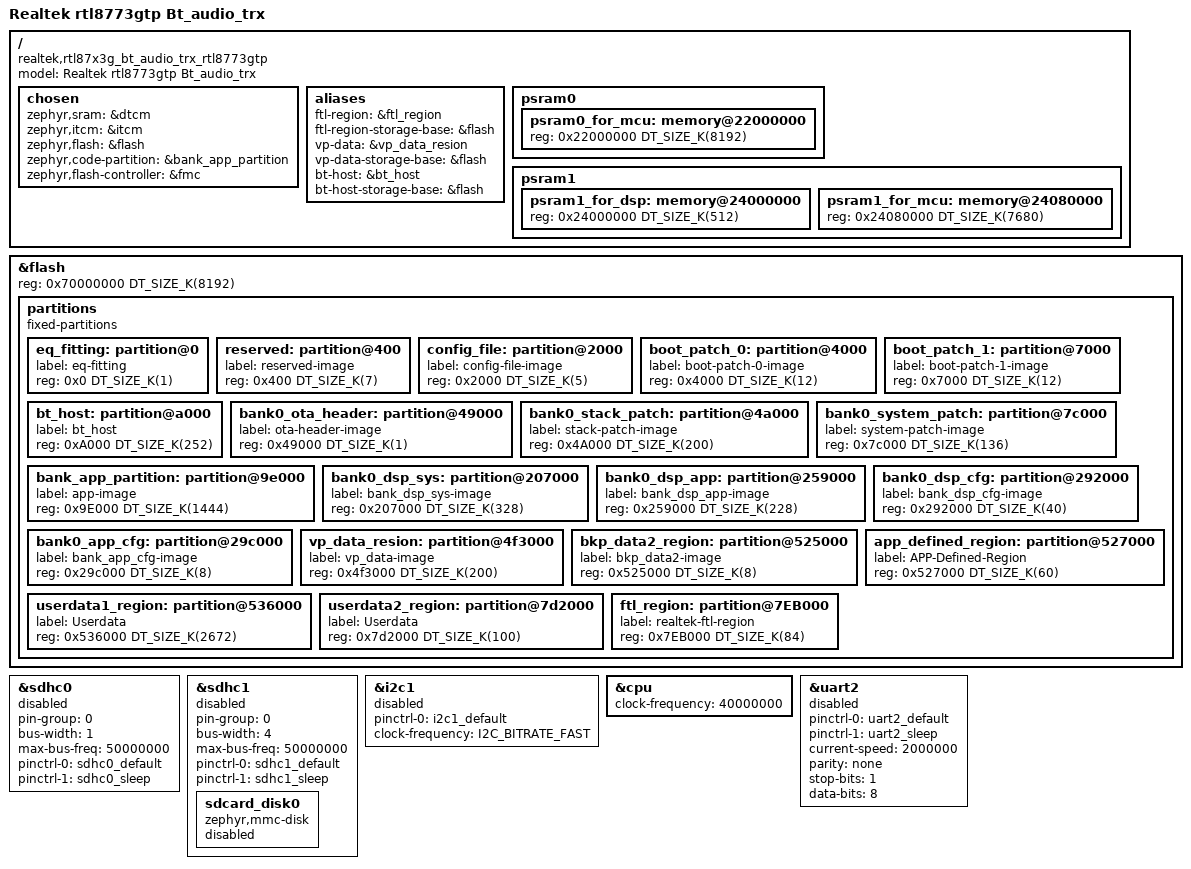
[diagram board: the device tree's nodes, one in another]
/*
 * Copyright (c) 2026, Realtek Semiconductor Corporation
 *
 * SPDX-License-Identifier: LicenseRef-Realtek-5-Clause
 */

/dts-v1/;
#include <realtek/rtl87x3g.dtsi>
#include "rtl87x3g_bt_audio_trx_rtl8783gbf-pinctrl.dtsi"
#include "board_pin_assignments/rtl8783gbf/board.h"
/ {
	model = "Realtek rtl8773gtp Bt_audio_trx";
	compatible = "realtek,rtl87x3g_bt_audio_trx_rtl8773gtp";
	chosen {
		zephyr,sram = &dtcm;
		zephyr,itcm = &itcm;
		zephyr,flash = &flash;
		zephyr,code-partition = &bank_app_partition;
//		zephyr,console = &uart2;
//		zephyr,shell-uart = &uart2;
		zephyr,flash-controller = &fmc;
	};
	/* These aliases are used by soc.c */
	aliases {
		ftl-region = &ftl_region;
		ftl-region-storage-base = &flash;
		vp-data = &vp_data_resion;
		vp-data-storage-base = &flash;
		bt-host = &bt_host;
		bt-host-storage-base = &flash;
	};
	
	psram0:psram0 {
		#address-cells = <1>;
		#size-cells = <1>;
		psram0_for_mcu: memory@22000000{
			device_type = "psram 0 region";
			reg = <0x22000000 DT_SIZE_K(8192)>;
		};
	};

	psram1:psram1 {
		#address-cells = <1>;
		#size-cells = <1>;

		psram1_for_dsp: memory@24000000{
			device_type = "psram 1 region for dsp";
			reg = <0x24000000 DT_SIZE_K(512)>;
		};
		
		psram1_for_mcu: memory@24080000{
			device_type = "psram 1 region";
			reg = <0x24080000 DT_SIZE_K(7680)>;
		};
	};
};

&flash
{
	reg = <0x70000000 DT_SIZE_K(8192)>;
	partitions {
	    compatible = "fixed-partitions";
		#address-cells = <1>;
		#size-cells = <1>;
		eq_fitting: partition@0 {
			label = "eq-fitting";
			reg = <0x0 DT_SIZE_K(1)>;
		};
		reserved: partition@400 {
			label = "reserved-image";
			reg = <0x400 DT_SIZE_K(7)>;
		};
		config_file: partition@2000 {
			label = "config-file-image";
			reg = <0x2000 DT_SIZE_K(5)>;
		};
		boot_patch_0: partition@4000 {
			label = "boot-patch-0-image";
			reg = <0x4000 DT_SIZE_K(12)>;
		};
		boot_patch_1: partition@7000 {
			label = "boot-patch-1-image";
			reg = <0x7000 DT_SIZE_K(12)>;
		};
		bt_host: partition@a000 {
			label = "bt_host";
			reg = <0xA000 DT_SIZE_K(252)>;
		};
		bank0_ota_header: partition@49000 {
			label = "ota-header-image";
			reg = <0x49000 DT_SIZE_K(1)>;
		};
		bank0_stack_patch: partition@4a000 {
			label = "stack-patch-image";
			reg = <0x4A000 DT_SIZE_K(200)>;
		};
		bank0_system_patch: partition@7c000 {
			label = "system-patch-image";
			reg = <0x7c000 DT_SIZE_K(136)>;
		};
		bank_app_partition: partition@9e000 {
			label = "app-image";
			reg = <0x9E000 DT_SIZE_K(1444)>;
		};
		bank0_dsp_sys: partition@207000 {
			label = "bank_dsp_sys-image";
			reg = <0x207000 DT_SIZE_K(328)>;
		};
		bank0_dsp_app: partition@259000 {
			label = "bank_dsp_app-image";
			reg = <0x259000 DT_SIZE_K(228)>;
		};
		bank0_dsp_cfg: partition@292000 {
			label = "bank_dsp_cfg-image";
			reg = <0x292000 DT_SIZE_K(40)>;
		};
		bank0_app_cfg: partition@29c000 {
			label = "bank_app_cfg-image";
			reg = <0x29c000 DT_SIZE_K(8)>;
		};
		vp_data_resion: partition@4f3000 {
			label = "vp_data-image";
			reg = <0x4f3000 DT_SIZE_K(200)>;
		};
		
		bkp_data2_region: partition@525000 {
			label = "bkp_data2-image";
			reg = <0x525000 DT_SIZE_K(8)>;
		};
		
		app_defined_region: partition@527000 {
			label = "APP-Defined-Region";
			reg = <0x527000 DT_SIZE_K(60)>;
		};
		
		userdata1_region: partition@536000 {
			label = "Userdata";
			reg = <0x536000 DT_SIZE_K(2672)>;
		};
		
		userdata2_region: partition@7d2000 {
			label = "Userdata";
			reg = <0x7d2000 DT_SIZE_K(100)>;
		};

		ftl_region: partition@7EB000 {
			label = "realtek-ftl-region";
			reg = <0x7EB000 DT_SIZE_K(84)>; 
		};
	};
};

&sdhc0 {
    pin-group = <0>;
    bus-width = <1>;
	max-bus-freq = <50000000>;
	/*P3_4       26  /*!< GPIOA6 */ 
    pinctrl-0 = <&sdhc0_default>;
    pinctrl-1 = <&sdhc0_sleep>;
    pinctrl-names = "default", "sleep";
    status = "disabled";
};

&sdhc1 {
    pin-group = <0>;
    bus-width = <4>;
	max-bus-freq = <50000000>;
	/*P3_4       26  /*!< GPIOA6 */ 
    pinctrl-0 = <&sdhc1_default>;
    pinctrl-1 = <&sdhc1_sleep>;
    pinctrl-names = "default", "sleep";
    status = "disabled";
	sdcard_disk0: sdcard_disk0 {
//	compatible = "zephyr,sdmmc-disk";
	compatible = "zephyr,mmc-disk";
		status = "disabled";
	};
};

&i2c1 {
	pinctrl-0 = <&i2c1_default>;
    pinctrl-names = "default";
	clock-frequency = <I2C_BITRATE_FAST>;
	status = "disabled";
};

&cpu {
	clock-frequency = <40000000>;
};

&uart2 {
	pinctrl-0 = <&uart2_default>;
	pinctrl-1 = <&uart2_sleep>;
	pinctrl-names = "default", "sleep";
	status = "disabled";
	current-speed = <2000000>;
	parity = "none";
	stop-bits = "1";
	data-bits = <8>;
};
